# ESP32S31_RADIO register map
Vendor: Espressif; Series: ESP32-S31; File version: 3.52
Registers are 32-bit, read-write, no defined reset value unless marked. A register's access mark holds for its fields unless they carry their own. Offsets are from the block's base; [hi:lo] are bit positions; {n}, {i} and the like mark numbered series; 'fields as' and 'values as' point back to an identical list.

## PHY_FEDATA_RECOVERED — Sparse FEDATA words absent from the public platform PAC.
Base 0x20100400
0x30 RX_FILTER_MODE_OPAQUE — Complete phy_rx_filter_mode performs a read-modify-write; individual fields remain unnamed.
0x40 TX_RX_RESET_OPAQUE — Complete phy_fe_txrx_reset performs a read-modify-write; individual fields remain unnamed.

## PHY_FECTRL_RECOVERED — Sparse FECTRL antenna words absent from the public platform PAC.
Base 0x20100800
{0x34+4i} ANTENNA_CONFIG_WORD_{i}_OPAQUE (i=0..3) — Read-modify-written by complete antenna configuration functions and saved/restored by complete phy_dig_reg_backup.

## PHY_FEDATA_WIFI_RECOVERED — Sparse FEDATA_WIFI words absent from the public platform PAC.
Base 0x20100C00
0x14 CFO_CONFIG_WORD_0_OPAQUE — Complete phy_bb_cfo_cfg reads and replaces this word; individual hardware fields remain unnamed.
0x18 FREQUENCY_CORRECTION_WORD_0_OPAQUE — Complete phy_freq_correct read-modify-writes this word; individual fields remain unnamed.
0x1C FREQUENCY_CORRECTION_WORD_1_OPAQUE — Complete phy_freq_correct read-modify-writes this word; individual fields remain unnamed.

## BLUETOOTH_INTERRUPT_BANK — Bluetooth controller interrupt programming, enable, status, acknowledgement, snapshot and diagnostic registers. This physical view is independent from the controller task lifecycle so ownership can transfer to the hard ISR without also exposing scheduler, sleep or memory-management state.
Base 0x20101000
0x0C IRQ_CONTROL_0 wo — BTDM interrupt setup and the complete reset leaf write the finite complete image 1. Inner action remains unknown.
  [31:0] COMMAND
0x10 IRQ_CONTROL_1 wo — BTDM interrupt teardown and the complete reset leaf write the finite complete image 1. Inner action remains unknown.
  [31:0] COMMAND
0x14 IRQ_CONTROL_2 wo — BTDM interrupt teardown and the complete reset leaf write the finite complete image 1. Inner action remains unknown.
  [31:0] COMMAND
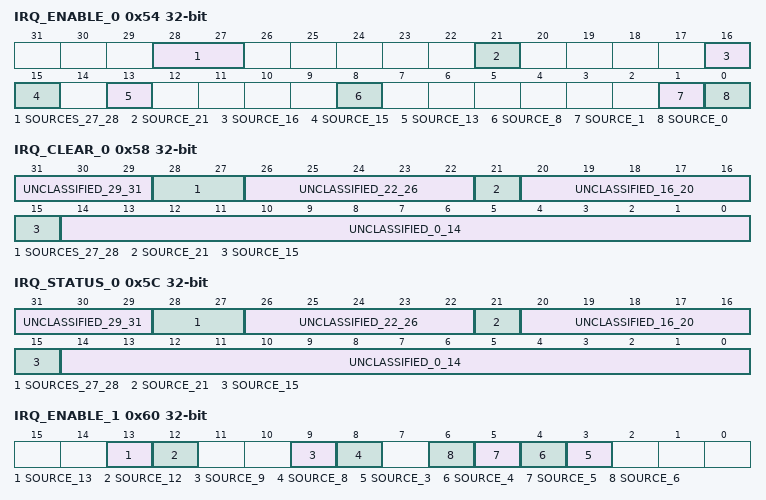
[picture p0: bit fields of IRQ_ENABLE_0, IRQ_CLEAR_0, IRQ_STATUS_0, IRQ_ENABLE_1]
0x54 IRQ_ENABLE_0 — First controller interrupt-enable bank. Primary setup clears stale image 0x00008000 then ORs that baseline into this word; another complete helper independently controls 0x18200000.
  [28:27] SOURCES_27_28, [21] SOURCE_21, [16] SOURCE_16, [15] SOURCE_15, [13] SOURCE_13, [8] SOURCE_8, [1] SOURCE_1, [0] SOURCE_0
0x58 IRQ_CLEAR_0 wo write-1-clears — First controller interrupt-clear bank. Primary and NRT handlers copy their respective first-bank status images here as complete words.
  [31:29] UNCLASSIFIED_29_31, [28:27] SOURCES_27_28, [26:22] UNCLASSIFIED_22_26, [21] SOURCE_21, [20:16] UNCLASSIFIED_16_20, [15] SOURCE_15, [14:0] UNCLASSIFIED_0_14
0x5C IRQ_STATUS_0 ro — First masked controller interrupt-status bank; the primary source-124 handler reads this complete word before acknowledgement.
  fields as IRQ_CLEAR_0
0x60 IRQ_ENABLE_1 — Second controller interrupt-enable bank. Primary setup clears stale image 0x00001300 then ORs that baseline into this word; another complete helper independently controls bit 3.
  [13] SOURCE_13, [12] SOURCE_12, [9] SOURCE_9, [8] SOURCE_8, [n] SOURCE_{n} (n=3..6)
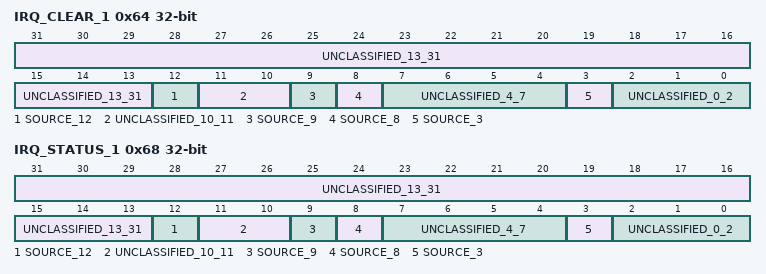
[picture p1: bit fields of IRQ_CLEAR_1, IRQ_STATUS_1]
0x64 IRQ_CLEAR_1 wo write-1-clears — Second controller interrupt-clear bank. Primary and NRT handlers copy their respective second-bank status images here as complete words.
  [31:13] UNCLASSIFIED_13_31, [12] SOURCE_12, [11:10] UNCLASSIFIED_10_11, [9] SOURCE_9, [8] SOURCE_8, [7:4] UNCLASSIFIED_4_7, [3] SOURCE_3, [2:0] UNCLASSIFIED_0_2
0x68 IRQ_STATUS_1 ro — Second masked controller interrupt-status bank; the primary source-124 handler reads this complete word before acknowledgement.
  fields as IRQ_CLEAR_1
0x70 IRQ_DIAGNOSTIC_STATE ro — Complete word read by the primary source-124 fault prefix when masked bank-one source 12 is pending. Inner state encoding remains unknown.
  [31:0] IMAGE
0x1C8 IRQ_DIAGNOSTIC_DETAIL_0 ro — First complete detail word read by the primary source-124 fault prefix when masked bank-one source 9 is pending. Inner encoding remains unknown.
  [31:0] IMAGE
0x1CC IRQ_DIAGNOSTIC_DETAIL_1 ro — Second complete detail word read by the primary source-124 fault prefix when masked bank-one source 9 is pending. Inner encoding remains unknown.
  [31:0] IMAGE
0x340 IRQ_STATUS_SNAPSHOT_0 ro — Raw first-bank status snapshot read by the NRT ISR and copied to IRQ_CLEAR_0.
  [31:0] PENDING_BITS
0x348 IRQ_STATUS_SNAPSHOT_1 ro — Raw second-bank status snapshot read by the NRT ISR and copied to IRQ_CLEAR_1.
  [31:0] PENDING_BITS
